VERSION "created by canmatrix"

NS_ :

BS_:

BU_: Jetson RT SYS MTR

BO_ 1 SAFETY_ESTOP: 0 RT

BO_ 17 SYS_SAFETY_STS: 2 SYS
 SG_ SYS_EstopActive : 7|8@0+ (1,0) [0|1] "" Vector__XXX
 SG_ SYS_HeartbeatOk : 15|8@0+ (1,0) [0|1] "" Vector__XXX

BO_ 18 SYS_DCDC_CMD: 1 SYS
 SG_ SYS_DcdcEnable : 7|8@0+ (1,0) [0|1] "" Vector__XXX

BO_ 272 SYS_MODE_CMD: 1 SYS
 SG_ SYS_Mode : 7|8@0+ (1,0) [0|2] "enum" Vector__XXX

BO_ 288 SYS_THROTTLE_STS: 2 MTR
 SG_ SYS_ThrottleSpeed : 7|16@0- (1,0) [-500|3000] "mm/s" Vector__XXX

BO_ 516 RT_DRIVE_CMD: 5 RT
 SG_ RT_MotorSpeed : 7|32@0- (1,0) [-500|3000] "mm/s" Vector__XXX
 SG_ RT_Gear : 39|8@0+ (1,0) [0|3] "enum" Vector__XXX

BO_ 517 RT_BRAKE_CMD: 4 RT
 SG_ RT_BrakePressure : 7|32@0- (1,0) [0|20000] "kPa" Vector__XXX

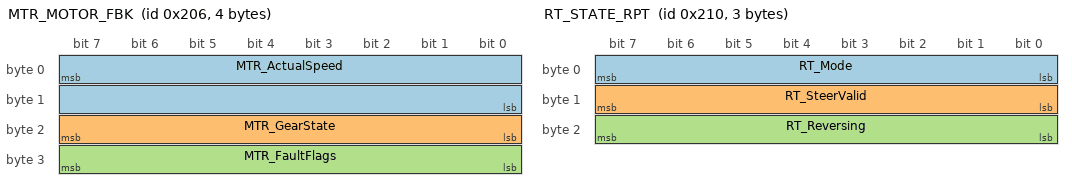
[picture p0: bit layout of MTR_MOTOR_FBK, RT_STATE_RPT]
BO_ 518 MTR_MOTOR_FBK: 4 MTR
 SG_ MTR_ActualSpeed : 7|16@0- (1,0) [-500|3000] "mm/s" Vector__XXX
 SG_ MTR_GearState : 23|8@0+ (1,0) [0|3] "enum" Vector__XXX
 SG_ MTR_FaultFlags : 31|8@0+ (1,0) [0|255] "" Vector__XXX

BO_ 528 RT_STATE_RPT: 3 RT
 SG_ RT_Mode : 7|8@0+ (1,0) [0|2] "enum" Vector__XXX
 SG_ RT_SteerValid : 15|8@0+ (1,0) [0|1] "" Vector__XXX
 SG_ RT_Reversing : 23|8@0+ (1,0) [0|1] "" Vector__XXX

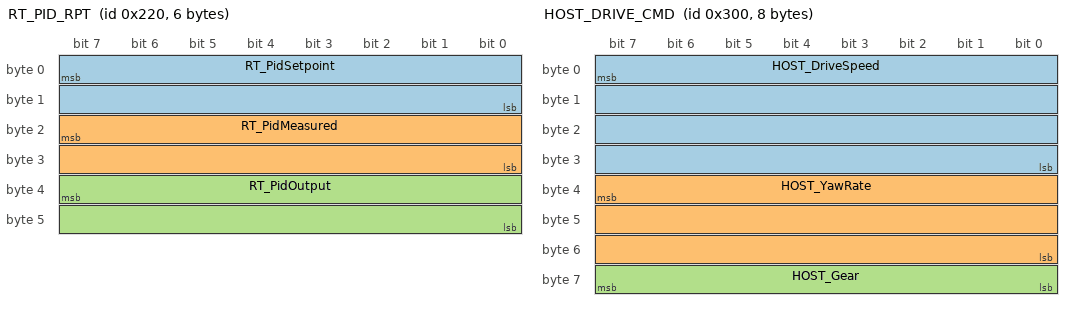
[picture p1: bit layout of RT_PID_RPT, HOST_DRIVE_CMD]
BO_ 544 RT_PID_RPT: 6 RT
 SG_ RT_PidSetpoint : 7|16@0- (1,0) [-32768|32767] "mm/s" Vector__XXX
 SG_ RT_PidMeasured : 23|16@0- (1,0) [-32768|32767] "mm/s" Vector__XXX
 SG_ RT_PidOutput : 39|16@0- (1,0) [-32768|32767] "" Vector__XXX

BO_ 768 HOST_DRIVE_CMD: 8 Jetson
 SG_ HOST_DriveSpeed : 7|32@0- (1,0) [-500|3000] "mm/s" Vector__XXX
 SG_ HOST_YawRate : 39|24@0- (1,0) [-3000|3000] "mrad/s" Vector__XXX
 SG_ HOST_Gear : 63|8@0+ (1,0) [0|3] "enum" Vector__XXX

BO_ 769 HOST_BRAKE_REQ: 4 Jetson
 SG_ HOST_BrakePressure : 7|32@0- (1,0) [0|20000] "kPa" Vector__XXX

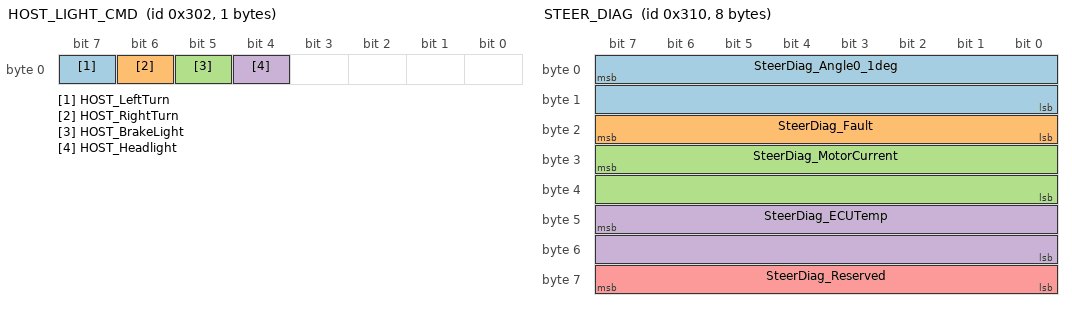
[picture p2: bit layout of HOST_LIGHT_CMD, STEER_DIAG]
BO_ 770 HOST_LIGHT_CMD: 1 Jetson
 SG_ HOST_LeftTurn : 7|1@0+ (1,0) [0|1] "" Vector__XXX
 SG_ HOST_RightTurn : 6|1@0+ (1,0) [0|1] "" Vector__XXX
 SG_ HOST_BrakeLight : 5|1@0+ (1,0) [0|1] "" Vector__XXX
 SG_ HOST_Headlight : 4|1@0+ (1,0) [0|1] "" Vector__XXX

BO_ 784 STEER_DIAG: 8 RT
 SG_ SteerDiag_Angle0_1deg : 7|16@0- (0.1000000000000000055511151231257827021181583404541015625,-3000) [-32768|32767] "deg" Vector__XXX
 SG_ SteerDiag_Fault : 23|8@0+ (1,0) [0|1] "" Vector__XXX
 SG_ SteerDiag_MotorCurrent : 31|16@0+ (0.01000000000000000020816681711721685132943093776702880859375,0) [0|65535] "A" Vector__XXX
 SG_ SteerDiag_ECUTemp : 47|16@0+ (0.1000000000000000055511151231257827021181583404541015625,0) [0|65535] "degC" Vector__XXX
 SG_ SteerDiag_Reserved : 63|8@0+ (1,0) [0|0] "" Vector__XXX

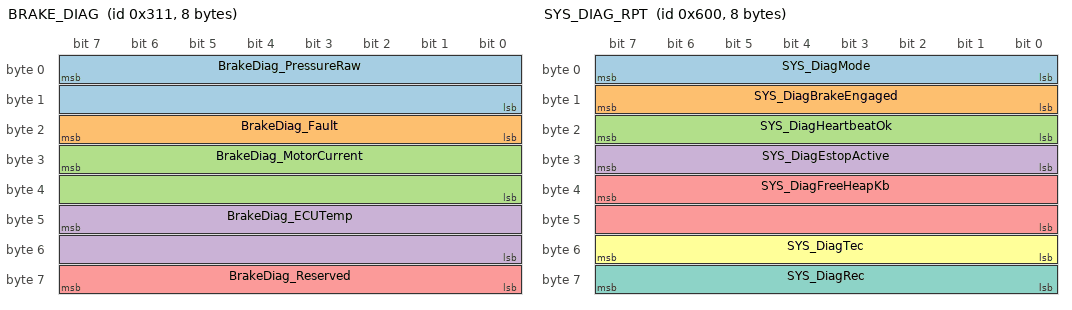
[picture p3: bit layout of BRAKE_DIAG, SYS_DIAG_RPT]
BO_ 785 BRAKE_DIAG: 8 RT
 SG_ BrakeDiag_PressureRaw : 7|16@0+ (0.05000000000000000277555756156289135105907917022705078125,0) [0|65535] "MPa" Vector__XXX
 SG_ BrakeDiag_Fault : 23|8@0+ (1,0) [0|1] "" Vector__XXX
 SG_ BrakeDiag_MotorCurrent : 31|16@0+ (0.01000000000000000020816681711721685132943093776702880859375,0) [0|65535] "A" Vector__XXX
 SG_ BrakeDiag_ECUTemp : 47|16@0+ (0.1000000000000000055511151231257827021181583404541015625,0) [0|65535] "degC" Vector__XXX
 SG_ BrakeDiag_Reserved : 63|8@0+ (1,0) [0|0] "" Vector__XXX

BO_ 1024 HOST_OBSTACLE_DIST: 4 Jetson
 SG_ HOST_ObstacleDistance : 7|32@0+ (1,0) [0|4294967295] "mm" Vector__XXX

BO_ 1536 SYS_DIAG_RPT: 8 SYS
 SG_ SYS_DiagMode : 7|8@0+ (1,0) [0|2] "" Vector__XXX
 SG_ SYS_DiagBrakeEngaged : 15|8@0+ (1,0) [0|1] "" Vector__XXX
 SG_ SYS_DiagHeartbeatOk : 23|8@0+ (1,0) [0|1] "" Vector__XXX
 SG_ SYS_DiagEstopActive : 31|8@0+ (1,0) [0|1] "" Vector__XXX
 SG_ SYS_DiagFreeHeapKb : 39|16@0+ (1,0) [0|65535] "KB" Vector__XXX
 SG_ SYS_DiagTec : 55|8@0+ (1,0) [0|255] "" Vector__XXX
 SG_ SYS_DiagRec : 63|8@0+ (1,0) [0|255] "" Vector__XXX

BO_ 2044 JETSON_HEARTBEAT: 1 Jetson
 SG_ Jetson_AliveCtr : 7|8@0+ (1,0) [0|255] "" Vector__XXX

BO_ 2045 RT_HEARTBEAT: 1 RT
 SG_ RT_AliveCtr : 7|8@0+ (1,0) [0|255] "" Vector__XXX

BO_ 2046 SYS_HEARTBEAT: 1 SYS
 SG_ SYS_AliveCtr : 7|8@0+ (1,0) [0|255] "" Vector__XXX

CM_ BO_ 1  "DLC=0  the frame ID itself is the ESTOP signal. Any node can send (RT is nominal). Bridged bidirectionally. Highest priority CAN frame.";
CM_ BO_ 17  "Forwarded low->high by RT. Same payload on both buses.";
CM_ BO_ 18  "DC-DC converter control. Low bus only.";
CM_ BO_ 272  "0=Manual, 1=Auto, 2=ESTOP. Low bus only.";
CM_ BO_ 288  "Current vehicle speed from MTR STM32. Forwarded low->high by RT. SYS_ prefix is historical.";
CM_ BO_ 516  "MTR receives for motor actuation. SYS receives for EGAS L2 monitoring. ID 0x204 avoids collision with EPS-C 0x202.";
CM_ BO_ 517  "RT max-select: max(rt_obstacle, jetson_0x301) -> SYS SEB cmd.";
CM_ BO_ 518  "Motor feedback from STM32. Low bus only.";
CM_ BO_ 528  "RT state report to Jetson. High bus only.";
CM_ BO_ 544  "RESERVED, inactive. PID telemetry for Jetson debugging.";
CM_ BO_ 768  "Jetson Autoware.Auto drive command -> RT. High bus only.";
CM_ BO_ 769  "On demand. RT arbitrates: max(RT_computed, HOST_request) -> 0x205.";
CM_ BO_ 770  "Forwarded transparently high->low by RT.";
CM_ BO_ 784  "Steering telemetry to Jetson. v0.0.4  previously missing from DBC.";
CM_ BO_ 785  "Brake telemetry to Jetson. v0.0.4  previously missing from DBC.";
CM_ BO_ 1024  "Jetson sends min obstacle distance (from LiDAR/camera perception) to RT at 10 Hz. High bus only.";
CM_ BO_ 1536  "SYS diagnostics report. Forwarded low->high by RT.";
CM_ BO_ 2044  "Not bridged, high bus only. Loss triggers controlled stop, not ESTOP.";
CM_ BO_ 2045  "RT sends independently on both buses (per-bus, NOT bridged). Separate counters.";
CM_ BO_ 2046  "Low bus only, never leaves low bus.";

CM_ SG_ 17 SYS_HeartbeatOk "0=RT alive counter frozen >1000ms, 1=incrementing";
CM_ SG_ 18 SYS_DcdcEnable "ESTOP->1(on); maintains 12V for MCUs, CAN transceivers, brake light";
CM_ SG_ 518 MTR_FaultFlags "bit0=ESTOP, bit1=CMD timeout, bit2=ADC fault, bit3=gear conflict";
CM_ SG_ 768 HOST_DriveSpeed "ROS 2: linear.x * 1000";
CM_ SG_ 768 HOST_YawRate "ROS 2: angular.z * 1000. i24 big-endian at bytes 4-6.";
CM_ SG_ 784 SteerDiag_Angle0_1deg "Actual steering angle. physical_deg = raw * 0.1 - 3000. Raw 30000 -> 0deg.";
CM_ SG_ 784 SteerDiag_Fault "0=OK, 1=EPS-C fault";
CM_ SG_ 784 SteerDiag_MotorCurrent "EPS-C motor current, 0.01A/bit";
CM_ SG_ 784 SteerDiag_ECUTemp "EPS-C ECU temperature, 0.1degC/bit";
CM_ SG_ 785 BrakeDiag_PressureRaw "SEB pressure raw, 0.05 MPa/bit";
CM_ SG_ 785 BrakeDiag_Fault "0=OK, 1=SEB fault";
CM_ SG_ 785 BrakeDiag_MotorCurrent "SEB motor current, 0.01A/bit";
CM_ SG_ 785 BrakeDiag_ECUTemp "SEB ECU temperature, 0.1degC/bit";
CM_ SG_ 1024 HOST_ObstacleDistance "UINT32_MAX = no reading / timeout";
CM_ SG_ 2044 Jetson_AliveCtr "Timeout 1500ms -> controlled stop. Jetson is QM, not safety-critical.";
CM_ SG_ 2045 RT_AliveCtr "Low bus timeout 1000ms->SYS ESTOP; High bus 1500ms->Jetson stops /cmd_vel";
CM_ SG_ 2046 SYS_AliveCtr "10 Hz / 200ms timeout -> RT brake takeover + ESTOP";

CM_ BU_ Jetson "Orin NX, Linux + ROS 2, perception/planning";
CM_ BU_ RT "ESP32-S3, FreeRTOS, realtime kinematics + CAN gateway";
CM_ BU_ SYS "ESP32-S3, FreeRTOS, safety + motor + body control";
CM_ BU_ MTR "STM32, bare metal, motor DAC + gear relays (EGAS L1)";

BA_DEF_ BO_ "GenMsgCycleTime" INT 0 65535;

BA_ "GenMsgCycleTime" BO_ 17 200;
BA_ "GenMsgCycleTime" BO_ 18 100;
BA_ "GenMsgCycleTime" BO_ 288 10;
BA_ "GenMsgCycleTime" BO_ 516 10;
BA_ "GenMsgCycleTime" BO_ 517 20;
BA_ "GenMsgCycleTime" BO_ 518 20;
BA_ "GenMsgCycleTime" BO_ 528 100;
BA_ "GenMsgCycleTime" BO_ 544 100;
BA_ "GenMsgCycleTime" BO_ 768 10;
BA_ "GenMsgCycleTime" BO_ 784 100;
BA_ "GenMsgCycleTime" BO_ 785 100;
BA_ "GenMsgCycleTime" BO_ 1024 100;
BA_ "GenMsgCycleTime" BO_ 1536 1000;
BA_ "GenMsgCycleTime" BO_ 2044 500;
BA_ "GenMsgCycleTime" BO_ 2045 500;
BA_ "GenMsgCycleTime" BO_ 2046 100;

VAL_ 272 SYS_Mode 0 "Manual" 1 "Auto" 2 "ESTOP";
VAL_ 516 RT_Gear 0 "N" 1 "D" 2 "S" 3 "R";
VAL_ 518 MTR_GearState 0 "N" 1 "D" 2 "S" 3 "R";
VAL_ 518 MTR_FaultFlags 1 "Overcurrent" 2 "Overtemp" 4 "CommsLoss";
VAL_ 528 RT_Mode 0 "Manual" 1 "Auto" 2 "ESTOP";
VAL_ 768 HOST_Gear 0 "N" 1 "D" 2 "S" 3 "R";
